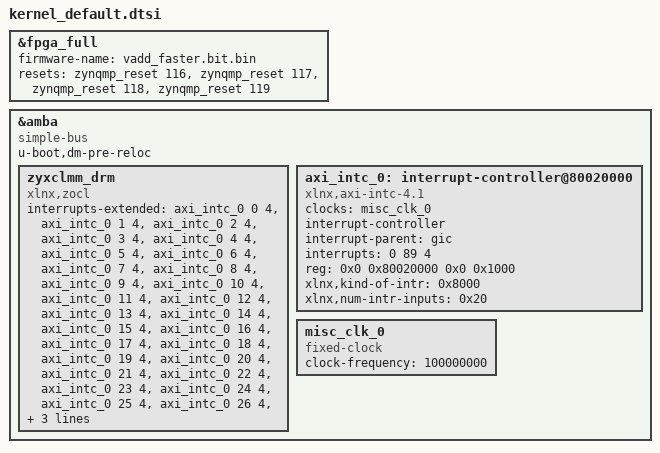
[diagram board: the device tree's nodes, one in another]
/dts-v1/;
/plugin/;

&fpga_full {
	#address-cells = <2>;
	#size-cells = <2>;
	firmware-name = "vadd_faster.bit.bin";
	resets = <&zynqmp_reset 116>, <&zynqmp_reset 117>, <&zynqmp_reset 118>, <&zynqmp_reset 119>;
};

&amba {
	compatible = "simple-bus";
	u-boot,dm-pre-reloc;
	#address-cells = <0x02>;
	#size-cells = <0x02>;

	zyxclmm_drm {
		// compatible = "xlnx,zocl";
		// status = "okay";
		compatible = "xlnx,zocl";
		interrupts-extended = <&axi_intc_0 0 4>, <&axi_intc_0 1 4>, <&axi_intc_0 2 4>, <&axi_intc_0 3 4>, <&axi_intc_0 4 4>, <&axi_intc_0 5 4>, 
			<&axi_intc_0 6 4>, <&axi_intc_0 7 4>, <&axi_intc_0 8 4>, <&axi_intc_0 9 4>,
			<&axi_intc_0 10 4>, <&axi_intc_0 11 4>, <&axi_intc_0 12 4>, <&axi_intc_0 13 4>, <&axi_intc_0 14 4>,
			<&axi_intc_0 15 4>, <&axi_intc_0 16 4>, <&axi_intc_0 17 4>, <&axi_intc_0 18 4>, <&axi_intc_0 19 4>,
			<&axi_intc_0 20 4>, <&axi_intc_0 21 4>, <&axi_intc_0 22 4>, <&axi_intc_0 23 4>, <&axi_intc_0 24 4>,
			<&axi_intc_0 25 4>, <&axi_intc_0 26 4>, <&axi_intc_0 27 4>, <&axi_intc_0 28 4>, <&axi_intc_0 29 4>,
			<&axi_intc_0 30 4>, <&axi_intc_0 31 4 >;
	};

	axi_intc_0: interrupt-controller@80020000 {
		#interrupt-cells = <2>;
		clock-names = "s_axi_aclk";
		clocks = <&misc_clk_0>;
		compatible = "xlnx,axi-intc-4.1", "xlnx,xps-intc-1.00.a";
		interrupt-controller ;
		interrupt-names = "irq";
		interrupt-parent = <&gic>;
		// interrupt-parent = <"/axi/interrupt-controller@f9010000">;
		interrupts = <0 89 4>;
		reg = <0x0 0x80020000 0x0 0x1000>;
		xlnx,kind-of-intr = <0x8000>;
		xlnx,num-intr-inputs = <0x20>;
	};

	misc_clk_0: misc_clk_0 {
		#clock-cells = <0>;
		clock-frequency = <100000000>;
		compatible = "fixed-clock";
	};
};
